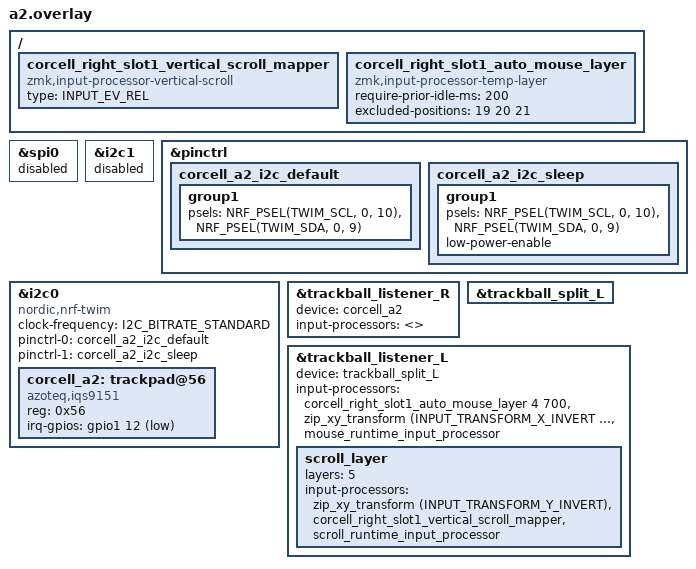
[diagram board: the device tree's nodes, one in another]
#include <dt-bindings/pinctrl/nrf-pinctrl.h>
#include <dt-bindings/zmk/input_transform.h>
#include <zephyr/dt-bindings/gpio/gpio.h>
#include <zephyr/dt-bindings/i2c/i2c.h>
#include <zephyr/dt-bindings/input/input-event-codes.h>
#include <input/processors.dtsi>

/* Right FPC: 1 RESET unused (JP1 open), 2 SCL, 3 RDY, 4 SDA, 5 3V3, 6 GND.
 * i2c0 shares the peripheral address with spi0. Never enable both.
 * The A2 PCB already has 4.7k pull-ups on SCL/SDA/RDY.
 */
&spi0 { status = "disabled"; };
&i2c1 { status = "disabled"; };

&pinctrl {
    corcell_a2_i2c_default: corcell_a2_i2c_default {
        group1 {
            psels = <NRF_PSEL(TWIM_SCL, 0, 10)>, <NRF_PSEL(TWIM_SDA, 0, 9)>;
        };
    };
    corcell_a2_i2c_sleep: corcell_a2_i2c_sleep {
        group1 {
            psels = <NRF_PSEL(TWIM_SCL, 0, 10)>, <NRF_PSEL(TWIM_SDA, 0, 9)>;
            low-power-enable;
        };
    };
};

&i2c0 {
    compatible = "nordic,nrf-twim";
    status = "okay";
    clock-frequency = <I2C_BITRATE_STANDARD>;
    pinctrl-0 = <&corcell_a2_i2c_default>;
    pinctrl-1 = <&corcell_a2_i2c_sleep>;
    pinctrl-names = "default", "sleep";
    corcell_a2: trackpad@56 {
        compatible = "azoteq,iqs9151";
        reg = <0x56>;
        status = "okay";
        irq-gpios = <&gpio1 12 GPIO_ACTIVE_LOW>;
        /* reset-gpios intentionally absent: connector pin 1 is isolated. */
    };
};

/ {
    corcell_right_slot1_vertical_scroll_mapper: corcell_right_slot1_vertical_scroll_mapper {
        compatible = "zmk,input-processor-vertical-scroll";
        #input-processor-cells = <0>;
        type = <INPUT_EV_REL>;
    };
    corcell_right_slot1_auto_mouse_layer: corcell_right_slot1_auto_mouse_layer {
        compatible = "zmk,input-processor-temp-layer";
        #input-processor-cells = <2>;
        require-prior-idle-ms = <200>;
        excluded-positions = <19 20 21>;
    };
};

&trackball_listener_R {
    status = "okay";
    device = <&corcell_a2>;
    input-processors = <>;
};

/* Input relayed from the left half. */
&trackball_split_L {
    status = "okay";
};

&trackball_listener_L {
    status = "okay";
    device = <&trackball_split_L>;
    /*
     * The left FPC slot is the mirror image of the right one, so the same
     * module sits rotated 180 degrees and needs no inversion. The transform
     * here cancels the x-invert/y-invert baked into the runtime processor.
     */
    input-processors =
        <&corcell_right_slot1_auto_mouse_layer 4 700>,
        <&zip_xy_transform (INPUT_TRANSFORM_X_INVERT | INPUT_TRANSFORM_Y_INVERT)>,
        <&mouse_runtime_input_processor>;

    scroll_layer {
        layers = <5>;
        input-processors =
            <&zip_xy_transform (INPUT_TRANSFORM_Y_INVERT)>,
            <&corcell_right_slot1_vertical_scroll_mapper>,
            <&scroll_runtime_input_processor>;
    };
};
